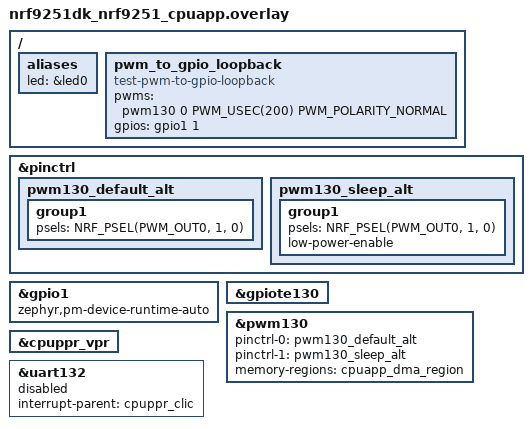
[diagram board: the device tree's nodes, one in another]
/*
 * Copyright (c) 2026 Nordic Semiconductor ASA
 *
 * SPDX-License-Identifier: LicenseRef-Nordic-5-Clause
 */

#include <zephyr/dt-bindings/pwm/pwm.h>
#include <zephyr/dt-bindings/gpio/nordic-nrf-gpio.h>

/* Test requires wire connection between:
 *  - PWM130 OUT[0] at P1.00
 *  - GPIO input at P1.01
 */

/ {
	aliases {
		led = &led0;
	};

	pwm_to_gpio_loopback: pwm_to_gpio_loopback {
		compatible = "test-pwm-to-gpio-loopback";
		pwms = <&pwm130 0 PWM_USEC(200) PWM_POLARITY_NORMAL>;
		gpios = <&gpio1 1 GPIO_ACTIVE_HIGH>;
	};
};

&pinctrl {
	pwm130_default_alt: pwm130_default_alt {
		group1 {
			psels = <NRF_PSEL(PWM_OUT0, 1, 0)>;
		};
	};

	pwm130_sleep_alt: pwm130_sleep_alt {
		group1 {
			psels = <NRF_PSEL(PWM_OUT0, 1, 0)>;
			low-power-enable;
		};
	};
};

&gpio1 {
	status = "okay";
	zephyr,pm-device-runtime-auto;
};

&gpiote130 {
	status = "okay";
};

&pwm130 {
	status = "okay";
	pinctrl-0 = <&pwm130_default_alt>;
	pinctrl-1 = <&pwm130_sleep_alt>;
	pinctrl-names = "default", "sleep";
	memory-regions = <&cpuapp_dma_region>;
};

&cpuppr_vpr {
	status = "okay";
};

&uart132 {
	status = "reserved";
	interrupt-parent = <&cpuppr_clic>;
};
